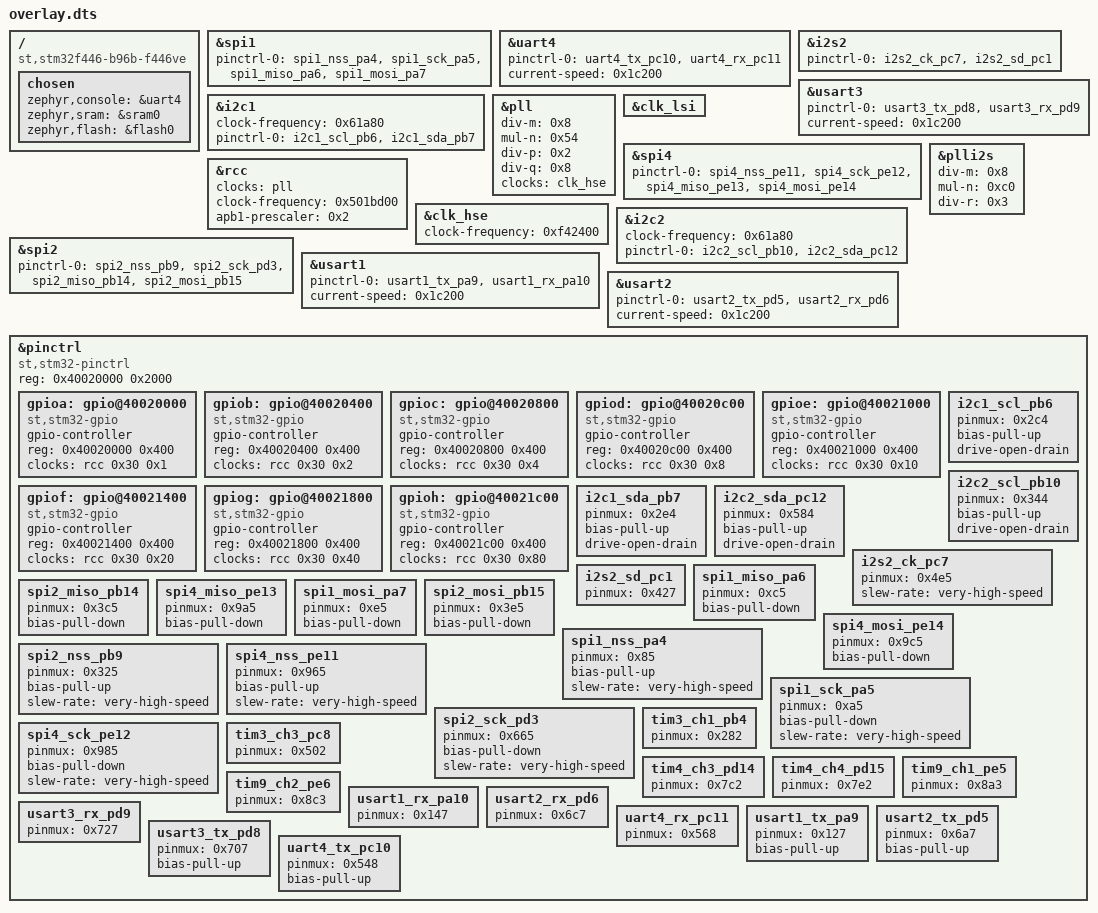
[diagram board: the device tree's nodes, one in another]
/ {
	compatible = "st,stm32f446-b96b-f446ve";
	chosen {
		zephyr,console = &uart4;
		zephyr,sram = &sram0;
		zephyr,flash = &flash0;
	};
};
&spi1{
	status = "okay";
	pinctrl-0 = < &spi1_nss_pa4 &spi1_sck_pa5 &spi1_miso_pa6 &spi1_mosi_pa7 >;
	pinctrl-names = "default";
};
&uart4{
	status = "okay";
	pinctrl-0 = < &uart4_tx_pc10 &uart4_rx_pc11 >;
	pinctrl-names = "default";
	current-speed = < 0x1c200 >;
};
&i2s2{
	status = "okay";
	pinctrl-0 = < &i2s2_ck_pc7 &i2s2_sd_pc1 >;
	pinctrl-names = "default";
};
&usart3{
	status = "okay";
	pinctrl-0 = < &usart3_tx_pd8 &usart3_rx_pd9 >;
	pinctrl-names = "default";
	current-speed = < 0x1c200 >;
};
&i2c1{
	clock-frequency = < 0x61a80 >;
	status = "okay";
	pinctrl-0 = < &i2c1_scl_pb6 &i2c1_sda_pb7 >;
	pinctrl-names = "default";
};
&pll{
	status = "okay";
	div-m = < 0x8 >;
	mul-n = < 0x54 >;
	div-p = < 0x2 >;
	div-q = < 0x8 >;
	clocks = < &clk_hse >;
};
&clk_lsi{
	status = "okay";
};
&spi4{
	status = "okay";
	pinctrl-0 = < &spi4_nss_pe11 &spi4_sck_pe12 &spi4_miso_pe13 &spi4_mosi_pe14 >;
	pinctrl-names = "default";
};
&rcc{
	clocks = < &pll >;
	clock-frequency = < 0x501bd00 >;
	apb1-prescaler = < 0x2 >;
};
&clk_hse{
	status = "okay";
	clock-frequency = < 0xf42400 >;
};
&plli2s{
	status = "okay";
	div-m = < 0x8 >;
	mul-n = < 0xc0 >;
	div-r = < 0x3 >;
};
&i2c2{
	clock-frequency = < 0x61a80 >;
	status = "okay";
	pinctrl-0 = < &i2c2_scl_pb10 &i2c2_sda_pc12 >;
	pinctrl-names = "default";
};
&spi2{
	pinctrl-0 = < &spi2_nss_pb9 &spi2_sck_pd3 &spi2_miso_pb14 &spi2_mosi_pb15 >;
	pinctrl-names = "default";
};
&usart1{
	status = "okay";
	pinctrl-0 = < &usart1_tx_pa9 &usart1_rx_pa10 >;
	pinctrl-names = "default";
	current-speed = < 0x1c200 >;
};
&usart2{
	status = "okay";
	pinctrl-0 = < &usart2_tx_pd5 &usart2_rx_pd6 >;
	pinctrl-names = "default";
	current-speed = < 0x1c200 >;
};
&pinctrl{
	compatible = "st,stm32-pinctrl";
	#address-cells = < 0x1 >;
	#size-cells = < 0x1 >;
	reg = < 0x40020000 0x2000 >;
	gpioa: gpio@40020000 {
		compatible = "st,stm32-gpio";
		gpio-controller;
		#gpio-cells = < 0x2 >;
		reg = < 0x40020000 0x400 >;
		clocks = < &rcc 0x30 0x1 >;
	};
	gpiob: gpio@40020400 {
		compatible = "st,stm32-gpio";
		gpio-controller;
		#gpio-cells = < 0x2 >;
		reg = < 0x40020400 0x400 >;
		clocks = < &rcc 0x30 0x2 >;
	};
	gpioc: gpio@40020800 {
		compatible = "st,stm32-gpio";
		gpio-controller;
		#gpio-cells = < 0x2 >;
		reg = < 0x40020800 0x400 >;
		clocks = < &rcc 0x30 0x4 >;
	};
	gpiod: gpio@40020c00 {
		compatible = "st,stm32-gpio";
		gpio-controller;
		#gpio-cells = < 0x2 >;
		reg = < 0x40020c00 0x400 >;
		clocks = < &rcc 0x30 0x8 >;
	};
	gpioe: gpio@40021000 {
		compatible = "st,stm32-gpio";
		gpio-controller;
		#gpio-cells = < 0x2 >;
		reg = < 0x40021000 0x400 >;
		clocks = < &rcc 0x30 0x10 >;
	};
	gpiof: gpio@40021400 {
		compatible = "st,stm32-gpio";
		gpio-controller;
		#gpio-cells = < 0x2 >;
		reg = < 0x40021400 0x400 >;
		clocks = < &rcc 0x30 0x20 >;
	};
	gpiog: gpio@40021800 {
		compatible = "st,stm32-gpio";
		gpio-controller;
		#gpio-cells = < 0x2 >;
		reg = < 0x40021800 0x400 >;
		clocks = < &rcc 0x30 0x40 >;
	};
	gpioh: gpio@40021c00 {
		compatible = "st,stm32-gpio";
		gpio-controller;
		#gpio-cells = < 0x2 >;
		reg = < 0x40021c00 0x400 >;
		clocks = < &rcc 0x30 0x80 >;
	};
	i2c1_scl_pb6: i2c1_scl_pb6 {
		pinmux = < 0x2c4 >;
		bias-pull-up;
		drive-open-drain;
	};
	i2c2_scl_pb10: i2c2_scl_pb10 {
		pinmux = < 0x344 >;
		bias-pull-up;
		drive-open-drain;
	};
	i2c1_sda_pb7: i2c1_sda_pb7 {
		pinmux = < 0x2e4 >;
		bias-pull-up;
		drive-open-drain;
	};
	i2c2_sda_pc12: i2c2_sda_pc12 {
		pinmux = < 0x584 >;
		bias-pull-up;
		drive-open-drain;
	};
	i2s2_ck_pc7: i2s2_ck_pc7 {
		pinmux = < 0x4e5 >;
		slew-rate = "very-high-speed";
	};
	i2s2_sd_pc1: i2s2_sd_pc1 {
		pinmux = < 0x427 >;
	};
	spi1_miso_pa6: spi1_miso_pa6 {
		pinmux = < 0xc5 >;
		bias-pull-down;
	};
	spi2_miso_pb14: spi2_miso_pb14 {
		pinmux = < 0x3c5 >;
		bias-pull-down;
	};
	spi4_miso_pe13: spi4_miso_pe13 {
		pinmux = < 0x9a5 >;
		bias-pull-down;
	};
	spi1_mosi_pa7: spi1_mosi_pa7 {
		pinmux = < 0xe5 >;
		bias-pull-down;
	};
	spi2_mosi_pb15: spi2_mosi_pb15 {
		pinmux = < 0x3e5 >;
		bias-pull-down;
	};
	spi4_mosi_pe14: spi4_mosi_pe14 {
		pinmux = < 0x9c5 >;
		bias-pull-down;
	};
	spi1_nss_pa4: spi1_nss_pa4 {
		pinmux = < 0x85 >;
		bias-pull-up;
		slew-rate = "very-high-speed";
	};
	spi2_nss_pb9: spi2_nss_pb9 {
		pinmux = < 0x325 >;
		bias-pull-up;
		slew-rate = "very-high-speed";
	};
	spi4_nss_pe11: spi4_nss_pe11 {
		pinmux = < 0x965 >;
		bias-pull-up;
		slew-rate = "very-high-speed";
	};
	spi1_sck_pa5: spi1_sck_pa5 {
		pinmux = < 0xa5 >;
		bias-pull-down;
		slew-rate = "very-high-speed";
	};
	spi2_sck_pd3: spi2_sck_pd3 {
		pinmux = < 0x665 >;
		bias-pull-down;
		slew-rate = "very-high-speed";
	};
	spi4_sck_pe12: spi4_sck_pe12 {
		pinmux = < 0x985 >;
		bias-pull-down;
		slew-rate = "very-high-speed";
	};
	tim3_ch1_pb4: tim3_ch1_pb4 {
		pinmux = < 0x282 >;
	};
	tim3_ch3_pc8: tim3_ch3_pc8 {
		pinmux = < 0x502 >;
	};
	tim4_ch3_pd14: tim4_ch3_pd14 {
		pinmux = < 0x7c2 >;
	};
	tim4_ch4_pd15: tim4_ch4_pd15 {
		pinmux = < 0x7e2 >;
	};
	tim9_ch1_pe5: tim9_ch1_pe5 {
		pinmux = < 0x8a3 >;
	};
	tim9_ch2_pe6: tim9_ch2_pe6 {
		pinmux = < 0x8c3 >;
	};
	usart1_rx_pa10: usart1_rx_pa10 {
		pinmux = < 0x147 >;
	};
	usart2_rx_pd6: usart2_rx_pd6 {
		pinmux = < 0x6c7 >;
	};
	usart3_rx_pd9: usart3_rx_pd9 {
		pinmux = < 0x727 >;
	};
	uart4_rx_pc11: uart4_rx_pc11 {
		pinmux = < 0x568 >;
	};
	usart1_tx_pa9: usart1_tx_pa9 {
		pinmux = < 0x127 >;
		bias-pull-up;
	};
	usart2_tx_pd5: usart2_tx_pd5 {
		pinmux = < 0x6a7 >;
		bias-pull-up;
	};
	usart3_tx_pd8: usart3_tx_pd8 {
		pinmux = < 0x707 >;
		bias-pull-up;
	};
	uart4_tx_pc10: uart4_tx_pc10 {
		pinmux = < 0x548 >;
		bias-pull-up;
	};
};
